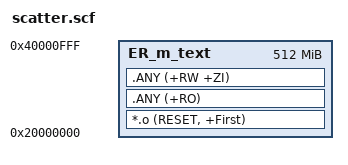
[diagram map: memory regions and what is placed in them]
#! armcc -E

#define m_text_start                   0x20000000
#define m_text_size                    0x20001000

LR_m_text m_text_start m_text_size {   ; load region size_region
  ER_m_text m_text_start m_text_size { ; load address = execution address
    *.o (RESET, +First)
    .ANY (+RO)
    
    .ANY (+RW +ZI)
  }
}
